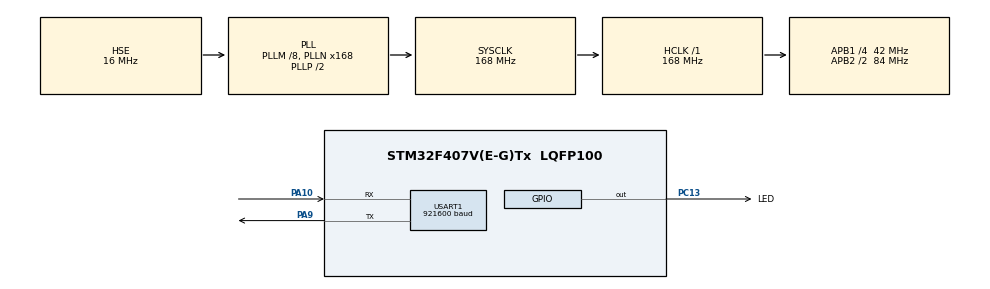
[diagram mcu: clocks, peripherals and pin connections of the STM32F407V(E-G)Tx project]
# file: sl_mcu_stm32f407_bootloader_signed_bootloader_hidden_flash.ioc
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Mcu.Family=STM32F4
Mcu.Name=STM32F407V(E-G)Tx
Mcu.Package=LQFP100
NVIC.PriorityGroup=NVIC_PRIORITYGROUP_4
PA10.Mode=Asynchronous
PA10.Signal=USART1_RX
PA13.Mode=Trace_Asynchronous_SW
PA13.Signal=SYS_JTMS-SWDIO
PA14.Mode=Trace_Asynchronous_SW
PA14.Signal=SYS_JTCK-SWCLK
PA9.Mode=Asynchronous
PA9.Signal=USART1_TX
PB3.Mode=Trace_Asynchronous_SW
PB3.Signal=SYS_JTDO-SWO
PC13-ANTI_TAMP.GPIO_Label=LED
PC13-ANTI_TAMP.GPIO_ModeDefaultOutputPP=GPIO_MODE_OUTPUT_OD
PC13-ANTI_TAMP.GPIO_PuPd=GPIO_NOPULL
PC13-ANTI_TAMP.PinState=GPIO_PIN_SET
PC13-ANTI_TAMP.Signal=GPIO_Output
PH0-OSC_IN.Mode=HSE-External-Oscillator
PH0-OSC_IN.Signal=RCC_OSC_IN
PH1-OSC_OUT.Mode=HSE-External-Oscillator
PH1-OSC_OUT.Signal=RCC_OSC_OUT
ProjectManager.HeapSize=0x200
ProjectManager.StackSize=0x400
ProjectManager.TargetToolchain=STM32CubeIDE
RCC.48MHZClocksFreq_Value=48000000
RCC.AHBFreq_Value=168000000
RCC.APB1CLKDivider=RCC_HCLK_DIV4
RCC.APB1Freq_Value=42000000
RCC.APB1TimFreq_Value=84000000
RCC.APB2CLKDivider=RCC_HCLK_DIV2
RCC.APB2Freq_Value=84000000
RCC.APB2TimFreq_Value=168000000
RCC.CortexFreq_Value=168000000
RCC.HCLKFreq_Value=168000000
RCC.HSE_VALUE=16000000
RCC.HSI_VALUE=16000000
RCC.LSE_VALUE=32768
RCC.PLLM=8
RCC.PLLN=168
RCC.PLLQ=7
RCC.PLLSourceVirtual=RCC_PLLSOURCE_HSE
RCC.SYSCLKFreq_VALUE=168000000
RCC.SYSCLKSource=RCC_SYSCLKSOURCE_PLLCLK
RCC.VCOOutputFreq_Value=336000000
USART1.BaudRate=921600
USART1.OverSampling=UART_OVERSAMPLING_8
USART1.VirtualMode=VM_ASYNC
board=custom

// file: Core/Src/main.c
/* USER CODE BEGIN Header */
/**
 ******************************************************************************
 * @file           : main.c
 * @brief          : Main program body
 ******************************************************************************
 * @attention
 *
 * Copyright (c) 2026 STM32World <lth@stm32world.com>
 * All rights reserved.
 *
 * This software is licensed under terms that can be found in the LICENSE file
 * in the root directory of this software component.
 * If no LICENSE file comes with this software, it is provided AS-IS.
 *
 ******************************************************************************
 */
/* USER CODE END Header */
#include "main.h"

/* USER CODE BEGIN Includes */
#include <stdio.h>
#include <string.h>
#include <stdbool.h>

/* USER CODE END Includes */

/* USER CODE BEGIN PTD */

typedef struct {
    uint32_t magic;          // 4 bytes: Magic identifier (e.g. 0x4150504B / "KAPP")
    uint32_t payload_len;    // 4 bytes: Size of binary firmware in bytes
    uint8_t signature[64];  // 64 bytes: ECDSA raw signature (32-byte R + 32-byte S)
    uint8_t reserved[56];   // 56 bytes: Zero padding to align header to 128 bytes
} Header128_t;

typedef void (*pFunction)(void);

/* USER CODE END PTD */

/* USER CODE BEGIN PD */

// #define printf(...)      // Nuke printf to save space
#define DFU_BOOT_FLAG 0xDEADBEEF
#define APP_ADDRESS 0x08008000
#define FIRMWARE_MAGIC 0x4150504B
#define STAGING_ADDRESS 0x08080000              // Sector 8 - start of the hidden upper 512 kB
#define STAGING_SECTOR FLASH_SECTOR_8
#define APP_MAX_SIZE (480 * 1024)               // Sectors 2-7

/* USER CODE END PD */

UART_HandleTypeDef huart1;

/* USER CODE BEGIN PV */
extern int _bflag;
uint32_t *dfu_boot_flag;
pFunction JumpToApplication;
uint32_t JumpAddress;

/* USER CODE END PV */

void SystemClock_Config(void);
static void MX_GPIO_Init(void);
static void MX_USART1_UART_Init(void);
/* USER CODE BEGIN PFP */

static bool flash_stm32_app(uint32_t src_addr, uint32_t dst_addr, uint32_t length);
static bool erase_staging(void);

/* USER CODE END PFP */

/* USER CODE BEGIN 0 */

// Send printf to uart1
int __io_putchar(int ch) {
    if (ch == '\n') {
        HAL_UART_Transmit(&huart1, (uint8_t*) "\r", 1, HAL_MAX_DELAY);
    }
    if (HAL_UART_Transmit(&huart1, (uint8_t*) &ch, 1, HAL_MAX_DELAY) != HAL_OK) {
        return -1;
    }
    return ch;
}

/**
 * @brief Erases the application sectors (2-7) and copies the payload from the hidden staging area
 */
static bool flash_stm32_app(uint32_t src_addr, uint32_t dst_addr, uint32_t length) {

    HAL_FLASH_Unlock();

    // Erase application sectors only (2-7) - sectors 8-11 hold the staged image
    FLASH_EraseInitTypeDef EraseInitStruct;
    uint32_t SectorError = 0;

    EraseInitStruct.TypeErase = FLASH_TYPEERASE_SECTORS;
    EraseInitStruct.VoltageRange = FLASH_VOLTAGE_RANGE_3;
    EraseInitStruct.Sector = FLASH_SECTOR_2; // Sector 2 starts at 0x08008000
    EraseInitStruct.NbSectors = 6;           // Sectors 2-7, up to 0x0807FFFF

    printf("[BOOT] Erasing STM32 internal Flash sectors 2-7...\n");
    if (HAL_FLASHEx_Erase(&EraseInitStruct, &SectorError) != HAL_OK) {
        printf("[BOOT] Error erasing internal flash sector %lu!\n", SectorError);
        HAL_FLASH_Lock();
        return false;
    }

    // Both source and destination are memory mapped, so copy word by word.
    // Rounding up to a whole word is harmless - the staging sector is erased beyond the payload.
    printf("[BOOT] Copying firmware 0x%08lX -> 0x%08lX (%lu bytes)...\n", src_addr, dst_addr, length);
    for (uint32_t offset = 0; offset < length; offset += 4) {
        uint32_t word = *(__IO uint32_t*) (src_addr + offset);
        if (HAL_FLASH_Program(FLASH_TYPEPROGRAM_WORD, dst_addr + offset, word) != HAL_OK) {
            printf("[BOOT] Programming failed at 0x%08lX!\n", dst_addr + offset);
            HAL_FLASH_Lock();
            return false;
        }
    }

    HAL_FLASH_Lock();
    printf("[BOOT] Internal Flash programming complete!\n");
    return true;
}

/**
 * @brief Erases the staging sector so the image is not flashed again on next boot
 */
static bool erase_staging(void) {
    FLASH_EraseInitTypeDef EraseInitStruct;
    uint32_t SectorError = 0;

    EraseInitStruct.TypeErase = FLASH_TYPEERASE_SECTORS;
    EraseInitStruct.VoltageRange = FLASH_VOLTAGE_RANGE_3;
    EraseInitStruct.Sector = STAGING_SECTOR;
    EraseInitStruct.NbSectors = 1;

    HAL_FLASH_Unlock();
    HAL_StatusTypeDef status = HAL_FLASHEx_Erase(&EraseInitStruct, &SectorError);
    HAL_FLASH_Lock();

    return status == HAL_OK;
}

/* USER CODE END 0 */

int main(void)
{

    /* USER CODE BEGIN 1 */

    // We handle all this before the HAL Libraries have been initialized.
    dfu_boot_flag = (uint32_t*) (&_bflag); // set in linker script

    if (*dfu_boot_flag != DFU_BOOT_FLAG) {

        /* Test if user code is programmed starting from address 0x08008000 */
        if (((*(__IO uint32_t*) APP_ADDRESS) & 0x2FFC0000) == 0x20000000) {

            /* Jump to user application */
            JumpAddress = *(__IO uint32_t*) (APP_ADDRESS + 4);
            JumpToApplication = (pFunction) JumpAddress;

            /* Initialize user application's Stack Pointer */
            __set_MSP(*(__IO uint32_t*) APP_ADDRESS);

            JumpToApplication();
        }

    }

    *dfu_boot_flag = 0; // So next boot won't be affected

    /* USER CODE END 1 */

    /* MCU Configuration--------------------------------------------------------*/

    /* Reset of all peripherals, Initializes the Flash interface and the Systick. */
    HAL_Init();

    /* Configure the system clock */
    SystemClock_Config();

    /* Initialize all configured peripherals */
    MX_GPIO_Init();
    MX_USART1_UART_Init();
    /* USER CODE BEGIN 2 */

    printf("\n\n\n\n--------\nBootloader\n");

    // The staged image header sits at the start of the hidden flash
    const Header128_t *header = (const Header128_t*) STAGING_ADDRESS;

    if (header->magic == FIRMWARE_MAGIC && header->payload_len > 0 && header->payload_len <= APP_MAX_SIZE) {
        printf("[BOOT] New firmware found in hidden flash (%lu bytes).\n", header->payload_len);

        if (flash_stm32_app(STAGING_ADDRESS + sizeof(Header128_t), APP_ADDRESS, header->payload_len)) {

            printf("[BOOT] Erasing staging sector...\n");
            if (!erase_staging()) {
                printf("[BOOT] ERROR: Failed to erase staging sector!\n");
            }

            printf("[BOOT] Firmware update complete. Rebooting MCU...\n");
            HAL_NVIC_SystemReset();

        } else {
            printf("[BOOT] ERROR: Failed to write internal flash!\n");
        }
    } else {
        printf("[BOOT] No valid firmware found in hidden flash.\n");
    }

    /* USER CODE END 2 */

    /* Infinite loop */
    /* USER CODE BEGIN WHILE */

    register uint32_t now = 0, loop_cnt = 0, next_blink = 100, next_tick = 1000;

    while (1) {

        now = uwTick;

        if (now >= next_blink) {
            HAL_GPIO_TogglePin(LED_GPIO_Port, LED_Pin);
            next_blink += 100;
        }

        if (now >= next_tick) {

            printf("Tick %lu (loop = %lu)\n", now / 1000, loop_cnt);

            loop_cnt = 0;
            next_tick = now + 1000;
        }

        ++loop_cnt;

        /* USER CODE END WHILE */

    }
}

void SystemClock_Config(void)
{
    RCC_OscInitTypeDef RCC_OscInitStruct = { 0 };
    RCC_ClkInitTypeDef RCC_ClkInitStruct = { 0 };

    /** Configure the main internal regulator output voltage
     */
    __HAL_RCC_PWR_CLK_ENABLE();
    __HAL_PWR_VOLTAGESCALING_CONFIG(PWR_REGULATOR_VOLTAGE_SCALE1);

    /** Initializes the RCC Oscillators according to the specified parameters
     * in the RCC_OscInitTypeDef structure.
     */
    RCC_OscInitStruct.OscillatorType = RCC_OSCILLATORTYPE_HSE;
    RCC_OscInitStruct.HSEState = RCC_HSE_ON;
    RCC_OscInitStruct.PLL.PLLState = RCC_PLL_ON;
    RCC_OscInitStruct.PLL.PLLSource = RCC_PLLSOURCE_HSE;
    RCC_OscInitStruct.PLL.PLLM = 8;
    RCC_OscInitStruct.PLL.PLLN = 168;
    RCC_OscInitStruct.PLL.PLLP = RCC_PLLP_DIV2;
    RCC_OscInitStruct.PLL.PLLQ = 7;
    if (HAL_RCC_OscConfig(&RCC_OscInitStruct) != HAL_OK)
            {
        Error_Handler();
    }

    /** Initializes the CPU, AHB and APB buses clocks
     */
    RCC_ClkInitStruct.ClockType = RCC_CLOCKTYPE_HCLK | RCC_CLOCKTYPE_SYSCLK
            | RCC_CLOCKTYPE_PCLK1 | RCC_CLOCKTYPE_PCLK2;
    RCC_ClkInitStruct.SYSCLKSource = RCC_SYSCLKSOURCE_PLLCLK;
    RCC_ClkInitStruct.AHBCLKDivider = RCC_SYSCLK_DIV1;
    RCC_ClkInitStruct.APB1CLKDivider = RCC_HCLK_DIV4;
    RCC_ClkInitStruct.APB2CLKDivider = RCC_HCLK_DIV2;

    if (HAL_RCC_ClockConfig(&RCC_ClkInitStruct, FLASH_LATENCY_5) != HAL_OK)
            {
        Error_Handler();
    }
}

static void MX_USART1_UART_Init(void)
{

    huart1.Instance = USART1;
    huart1.Init.BaudRate = 921600;
    huart1.Init.WordLength = UART_WORDLENGTH_8B;
    huart1.Init.StopBits = UART_STOPBITS_1;
    huart1.Init.Parity = UART_PARITY_NONE;
    huart1.Init.Mode = UART_MODE_TX_RX;
    huart1.Init.HwFlowCtl = UART_HWCONTROL_NONE;
    huart1.Init.OverSampling = UART_OVERSAMPLING_8;
    if (HAL_UART_Init(&huart1) != HAL_OK)
            {
        Error_Handler();
    }

}

static void MX_GPIO_Init(void)
{
    GPIO_InitTypeDef GPIO_InitStruct = { 0 };

    /* GPIO Ports Clock Enable */
    __HAL_RCC_GPIOC_CLK_ENABLE();
    __HAL_RCC_GPIOH_CLK_ENABLE();
    __HAL_RCC_GPIOA_CLK_ENABLE();
    __HAL_RCC_GPIOB_CLK_ENABLE();

    /*Configure GPIO pin Output Level */
    HAL_GPIO_WritePin(LED_GPIO_Port, LED_Pin, GPIO_PIN_SET);

    /*Configure GPIO pin : LED_Pin */
    GPIO_InitStruct.Pin = LED_Pin;
    GPIO_InitStruct.Mode = GPIO_MODE_OUTPUT_OD;
    GPIO_InitStruct.Pull = GPIO_NOPULL;
    GPIO_InitStruct.Speed = GPIO_SPEED_FREQ_LOW;
    HAL_GPIO_Init(LED_GPIO_Port, &GPIO_InitStruct);

}

void Error_Handler(void)
{
    __disable_irq();
    while (1)
    {
    }
}
